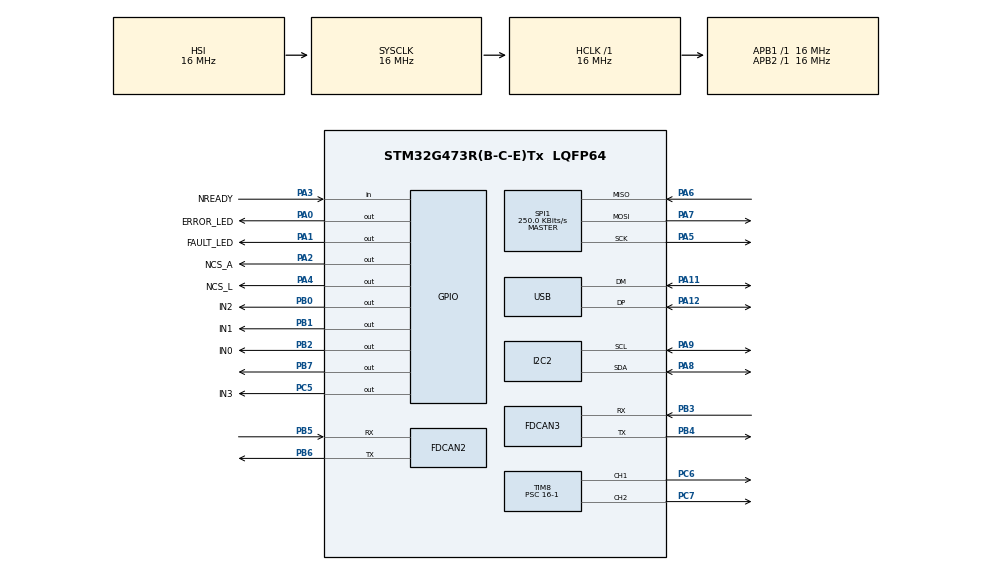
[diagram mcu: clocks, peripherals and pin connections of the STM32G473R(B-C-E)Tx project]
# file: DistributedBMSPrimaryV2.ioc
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FDCAN2.CalculateBaudRateNominal=500000
FDCAN2.CalculateTimeBitNominal=2000
FDCAN2.CalculateTimeQuantumNominal=250.0
FDCAN2.NominalPrescaler=4
FDCAN2.NominalTimeSeg1=3
FDCAN2.NominalTimeSeg2=4
FDCAN3.CalculateBaudRateNominal=500000
FDCAN3.CalculateTimeBitNominal=2000
FDCAN3.CalculateTimeQuantumNominal=250.0
FDCAN3.NominalPrescaler=4
FDCAN3.NominalTimeSeg1=3
FDCAN3.NominalTimeSeg2=4
FREERTOS.Tasks01=defaultTask,24,128,StartDefaultTask,Default,NULL,Dynamic,NULL,NULL
FREERTOS.configUSE_NEWLIB_REENTRANT=1
I2C2.Timing=0x00503D58
Mcu.Family=STM32G4
Mcu.Name=STM32G473R(B-C-E)Tx
Mcu.Package=LQFP64
NVIC.FDCAN2_IT0_IRQn=true\:5\:0\:false\:false\:true\:true\:true\:true\:true
NVIC.FDCAN3_IT0_IRQn=true\:5\:0\:false\:false\:true\:true\:true\:true\:true
NVIC.PriorityGroup=NVIC_PRIORITYGROUP_4
NVIC.TIM3_IRQn=true\:15\:0\:false\:false\:true\:false\:false\:true\:true
NVIC.TimeBase=TIM3_IRQn
NVIC.TimeBaseIP=TIM3
PA0.GPIO_Label=ERROR_LED
PA0.Signal=GPIO_Output
PA1.GPIO_Label=FAULT_LED
PA1.Signal=GPIO_Output
PA11.Mode=Device
PA11.Signal=USB_DM
PA12.Mode=Device
PA12.Signal=USB_DP
PA13.Mode=Serial_Wire
PA13.Signal=SYS_JTMS-SWDIO
PA14.Mode=Serial_Wire
PA14.Signal=SYS_JTCK-SWCLK
PA2.GPIO_Label=NCS_A
PA2.Signal=GPIO_Output
PA3.GPIO_Label=NREADY
PA3.Signal=GPIO_Input
PA4.GPIO_Label=NCS_L
PA4.Signal=GPIO_Output
PA5.Mode=Full_Duplex_Master
PA5.Signal=SPI1_SCK
PA6.Mode=Full_Duplex_Master
PA6.Signal=SPI1_MISO
PA7.Mode=Full_Duplex_Master
PA7.Signal=SPI1_MOSI
PA8.Mode=I2C
PA8.Signal=I2C2_SDA
PA9.Mode=I2C
PA9.Signal=I2C2_SCL
PB0.GPIO_Label=IN2
PB0.Signal=GPIO_Output
PB1.GPIO_Label=IN1
PB1.Signal=GPIO_Output
PB2.GPIO_Label=IN0
PB2.Signal=GPIO_Output
PB3.Mode=FDCAN_Activate
PB3.Signal=FDCAN3_RX
PB4.Mode=FDCAN_Activate
PB4.Signal=FDCAN3_TX
PB5.Mode=FDCAN_Activate
PB5.Signal=FDCAN2_RX
PB6.Mode=FDCAN_Activate
PB6.Signal=FDCAN2_TX
PB7.Signal=GPIO_Output
PC5.GPIO_Label=IN3
PC5.Signal=GPIO_Output
PC6.Signal=S_TIM8_CH1
PC7.Signal=S_TIM8_CH2
ProjectManager.HeapSize=0x200
ProjectManager.StackSize=0x400
ProjectManager.TargetToolchain=STM32CubeIDE
RCC.AHBFreq_Value=16000000
RCC.APB1Freq_Value=16000000
RCC.APB1TimFreq_Value=16000000
RCC.APB2Freq_Value=16000000
RCC.APB2TimFreq_Value=16000000
RCC.CortexFreq_Value=16000000
RCC.EXTERNAL_CLOCK_VALUE=12288000
RCC.HCLKFreq_Value=16000000
RCC.HSE_VALUE=8000000
RCC.HSI48_VALUE=48000000
RCC.HSI_VALUE=16000000
RCC.LSE_VALUE=32768
RCC.PLLN=12
RCC.PLLQ=RCC_PLLQ_DIV4
RCC.SYSCLKFreq_VALUE=16000000
RCC.USBFreq_Value=48000000
RCC.VCOOutputFreq_Value=192000000
SH.S_TIM8_CH1.0=TIM8_CH1,PWM Generation1 CH1
SH.S_TIM8_CH2.0=TIM8_CH2,PWM Generation2 CH2
SPI1.BaudRatePrescaler=SPI_BAUDRATEPRESCALER_64
SPI1.CalculateBaudRate=250.0 KBits/s
SPI1.DataSize=SPI_DATASIZE_8BIT
SPI1.Direction=SPI_DIRECTION_2LINES
SPI1.Mode=SPI_MODE_MASTER
SPI1.VirtualType=VM_MASTER
TIM8.Channel-PWM\ Generation1\ CH1=TIM_CHANNEL_1
TIM8.Channel-PWM\ Generation2\ CH2=TIM_CHANNEL_2
TIM8.OCMode_PWM-PWM\ Generation1\ CH1=TIM_OCMODE_PWM2
TIM8.PeriodNoDither=40-1
TIM8.Prescaler=16-1
VP_FREERTOS_VS_CMSIS_V2.Mode=CMSIS_V2
VP_SYS_VS_DBSignals.Mode=DisableDeadBatterySignals
VP_SYS_VS_tim3.Mode=TIM3
VP_TIM8_VS_ClockSourceINT.Mode=Internal
board=custom

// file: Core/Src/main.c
/* USER CODE BEGIN Header */
/**
  ******************************************************************************
  * @file           : main.c
  * @brief          : Main program body
  ******************************************************************************
  * @attention
  *
  * Copyright (c) 2026 STMicroelectronics.
  * All rights reserved.
  *
  * This software is licensed under terms that can be found in the LICENSE file
  * in the root directory of this software component.
  * If no LICENSE file comes with this software, it is provided AS-IS.
  *
  ******************************************************************************
  */
/* USER CODE END Header */
#include "main.h"
#include "cmsis_os.h"

FDCAN_HandleTypeDef hfdcan2;
FDCAN_HandleTypeDef hfdcan3;

I2C_HandleTypeDef hi2c2;

SPI_HandleTypeDef hspi1;

TIM_HandleTypeDef htim8;

/* Definitions for defaultTask */
osThreadId_t defaultTaskHandle;
const osThreadAttr_t defaultTask_attributes = {
  .name = "defaultTask",
  .priority = (osPriority_t) osPriorityNormal,
  .stack_size = 128 * 4
};

void SystemClock_Config(void);
static void MX_GPIO_Init(void);
static void MX_FDCAN2_Init(void);
static void MX_FDCAN3_Init(void);
static void MX_SPI1_Init(void);
static void MX_I2C2_Init(void);
static void MX_TIM8_Init(void);
void StartDefaultTask(void *argument);

int main(void)
{

  /* MCU Configuration--------------------------------------------------------*/

  /* Reset of all peripherals, Initializes the Flash interface and the Systick. */
  HAL_Init();

  /* Configure the system clock */
  SystemClock_Config();

  /* Initialize all configured peripherals */
  MX_GPIO_Init();
  MX_FDCAN2_Init();
  MX_FDCAN3_Init();
  MX_SPI1_Init();
  MX_I2C2_Init();
  MX_TIM8_Init();

  /* Init scheduler */
  osKernelInitialize();

  /* Create the thread(s) */
  /* creation of defaultTask */
  defaultTaskHandle = osThreadNew(StartDefaultTask, NULL, &defaultTask_attributes);

  /* Start scheduler */
  osKernelStart();

  /* We should never get here as control is now taken by the scheduler */

  /* Infinite loop */
  while (1)
  {

  }
}

void SystemClock_Config(void)
{
  RCC_OscInitTypeDef RCC_OscInitStruct = {0};
  RCC_ClkInitTypeDef RCC_ClkInitStruct = {0};

  /** Configure the main internal regulator output voltage
  */
  HAL_PWREx_ControlVoltageScaling(PWR_REGULATOR_VOLTAGE_SCALE1);

  /** Initializes the RCC Oscillators according to the specified parameters
  * in the RCC_OscInitTypeDef structure.
  */
  RCC_OscInitStruct.OscillatorType = RCC_OSCILLATORTYPE_HSI;
  RCC_OscInitStruct.HSIState = RCC_HSI_ON;
  RCC_OscInitStruct.HSICalibrationValue = RCC_HSICALIBRATION_DEFAULT;
  RCC_OscInitStruct.PLL.PLLState = RCC_PLL_NONE;
  if (HAL_RCC_OscConfig(&RCC_OscInitStruct) != HAL_OK)
  {
    Error_Handler();
  }

  /** Initializes the CPU, AHB and APB buses clocks
  */
  RCC_ClkInitStruct.ClockType = RCC_CLOCKTYPE_HCLK|RCC_CLOCKTYPE_SYSCLK
                              |RCC_CLOCKTYPE_PCLK1|RCC_CLOCKTYPE_PCLK2;
  RCC_ClkInitStruct.SYSCLKSource = RCC_SYSCLKSOURCE_HSI;
  RCC_ClkInitStruct.AHBCLKDivider = RCC_SYSCLK_DIV1;
  RCC_ClkInitStruct.APB1CLKDivider = RCC_HCLK_DIV1;
  RCC_ClkInitStruct.APB2CLKDivider = RCC_HCLK_DIV1;

  if (HAL_RCC_ClockConfig(&RCC_ClkInitStruct, FLASH_LATENCY_0) != HAL_OK)
  {
    Error_Handler();
  }
}

static void MX_FDCAN2_Init(void)
{

  hfdcan2.Instance = FDCAN2;
  hfdcan2.Init.ClockDivider = FDCAN_CLOCK_DIV1;
  hfdcan2.Init.FrameFormat = FDCAN_FRAME_CLASSIC;
  hfdcan2.Init.Mode = FDCAN_MODE_NORMAL;
  hfdcan2.Init.AutoRetransmission = DISABLE;
  hfdcan2.Init.TransmitPause = DISABLE;
  hfdcan2.Init.ProtocolException = DISABLE;
  hfdcan2.Init.NominalPrescaler = 4;
  hfdcan2.Init.NominalSyncJumpWidth = 1;
  hfdcan2.Init.NominalTimeSeg1 = 3;
  hfdcan2.Init.NominalTimeSeg2 = 4;
  hfdcan2.Init.DataPrescaler = 1;
  hfdcan2.Init.DataSyncJumpWidth = 1;
  hfdcan2.Init.DataTimeSeg1 = 1;
  hfdcan2.Init.DataTimeSeg2 = 1;
  hfdcan2.Init.StdFiltersNbr = 0;
  hfdcan2.Init.ExtFiltersNbr = 0;
  hfdcan2.Init.TxFifoQueueMode = FDCAN_TX_FIFO_OPERATION;
  if (HAL_FDCAN_Init(&hfdcan2) != HAL_OK)
  {
    Error_Handler();
  }

}

static void MX_FDCAN3_Init(void)
{

  hfdcan3.Instance = FDCAN3;
  hfdcan3.Init.ClockDivider = FDCAN_CLOCK_DIV1;
  hfdcan3.Init.FrameFormat = FDCAN_FRAME_CLASSIC;
  hfdcan3.Init.Mode = FDCAN_MODE_NORMAL;
  hfdcan3.Init.AutoRetransmission = DISABLE;
  hfdcan3.Init.TransmitPause = DISABLE;
  hfdcan3.Init.ProtocolException = DISABLE;
  hfdcan3.Init.NominalPrescaler = 4;
  hfdcan3.Init.NominalSyncJumpWidth = 1;
  hfdcan3.Init.NominalTimeSeg1 = 3;
  hfdcan3.Init.NominalTimeSeg2 = 4;
  hfdcan3.Init.DataPrescaler = 1;
  hfdcan3.Init.DataSyncJumpWidth = 1;
  hfdcan3.Init.DataTimeSeg1 = 1;
  hfdcan3.Init.DataTimeSeg2 = 1;
  hfdcan3.Init.StdFiltersNbr = 0;
  hfdcan3.Init.ExtFiltersNbr = 0;
  hfdcan3.Init.TxFifoQueueMode = FDCAN_TX_FIFO_OPERATION;
  if (HAL_FDCAN_Init(&hfdcan3) != HAL_OK)
  {
    Error_Handler();
  }

}

static void MX_I2C2_Init(void)
{

  hi2c2.Instance = I2C2;
  hi2c2.Init.Timing = 0x00503D58;
  hi2c2.Init.OwnAddress1 = 0;
  hi2c2.Init.AddressingMode = I2C_ADDRESSINGMODE_7BIT;
  hi2c2.Init.DualAddressMode = I2C_DUALADDRESS_DISABLE;
  hi2c2.Init.OwnAddress2 = 0;
  hi2c2.Init.OwnAddress2Masks = I2C_OA2_NOMASK;
  hi2c2.Init.GeneralCallMode = I2C_GENERALCALL_DISABLE;
  hi2c2.Init.NoStretchMode = I2C_NOSTRETCH_DISABLE;
  if (HAL_I2C_Init(&hi2c2) != HAL_OK)
  {
    Error_Handler();
  }

  /** Configure Analogue filter
  */
  if (HAL_I2CEx_ConfigAnalogFilter(&hi2c2, I2C_ANALOGFILTER_ENABLE) != HAL_OK)
  {
    Error_Handler();
  }

  /** Configure Digital filter
  */
  if (HAL_I2CEx_ConfigDigitalFilter(&hi2c2, 0) != HAL_OK)
  {
    Error_Handler();
  }

}

static void MX_SPI1_Init(void)
{

  /* SPI1 parameter configuration*/
  hspi1.Instance = SPI1;
  hspi1.Init.Mode = SPI_MODE_MASTER;
  hspi1.Init.Direction = SPI_DIRECTION_2LINES;
  hspi1.Init.DataSize = SPI_DATASIZE_8BIT;
  hspi1.Init.CLKPolarity = SPI_POLARITY_LOW;
  hspi1.Init.CLKPhase = SPI_PHASE_1EDGE;
  hspi1.Init.NSS = SPI_NSS_SOFT;
  hspi1.Init.BaudRatePrescaler = SPI_BAUDRATEPRESCALER_64;
  hspi1.Init.FirstBit = SPI_FIRSTBIT_MSB;
  hspi1.Init.TIMode = SPI_TIMODE_DISABLE;
  hspi1.Init.CRCCalculation = SPI_CRCCALCULATION_DISABLE;
  hspi1.Init.CRCPolynomial = 7;
  hspi1.Init.CRCLength = SPI_CRC_LENGTH_DATASIZE;
  hspi1.Init.NSSPMode = SPI_NSS_PULSE_ENABLE;
  if (HAL_SPI_Init(&hspi1) != HAL_OK)
  {
    Error_Handler();
  }

}

static void MX_TIM8_Init(void)
{

  TIM_ClockConfigTypeDef sClockSourceConfig = {0};
  TIM_MasterConfigTypeDef sMasterConfig = {0};
  TIM_OC_InitTypeDef sConfigOC = {0};
  TIM_BreakDeadTimeConfigTypeDef sBreakDeadTimeConfig = {0};

  htim8.Instance = TIM8;
  htim8.Init.Prescaler = 16-1;
  htim8.Init.CounterMode = TIM_COUNTERMODE_UP;
  htim8.Init.Period = 39;
  htim8.Init.ClockDivision = TIM_CLOCKDIVISION_DIV1;
  htim8.Init.RepetitionCounter = 0;
  htim8.Init.AutoReloadPreload = TIM_AUTORELOAD_PRELOAD_DISABLE;
  if (HAL_TIM_Base_Init(&htim8) != HAL_OK)
  {
    Error_Handler();
  }
  sClockSourceConfig.ClockSource = TIM_CLOCKSOURCE_INTERNAL;
  if (HAL_TIM_ConfigClockSource(&htim8, &sClockSourceConfig) != HAL_OK)
  {
    Error_Handler();
  }
  if (HAL_TIM_PWM_Init(&htim8) != HAL_OK)
  {
    Error_Handler();
  }
  sMasterConfig.MasterOutputTrigger = TIM_TRGO_RESET;
  sMasterConfig.MasterOutputTrigger2 = TIM_TRGO2_RESET;
  sMasterConfig.MasterSlaveMode = TIM_MASTERSLAVEMODE_DISABLE;
  if (HAL_TIMEx_MasterConfigSynchronization(&htim8, &sMasterConfig) != HAL_OK)
  {
    Error_Handler();
  }
  sConfigOC.OCMode = TIM_OCMODE_PWM2;
  sConfigOC.Pulse = 0;
  sConfigOC.OCPolarity = TIM_OCPOLARITY_HIGH;
  sConfigOC.OCNPolarity = TIM_OCNPOLARITY_HIGH;
  sConfigOC.OCFastMode = TIM_OCFAST_DISABLE;
  sConfigOC.OCIdleState = TIM_OCIDLESTATE_RESET;
  sConfigOC.OCNIdleState = TIM_OCNIDLESTATE_RESET;
  if (HAL_TIM_PWM_ConfigChannel(&htim8, &sConfigOC, TIM_CHANNEL_1) != HAL_OK)
  {
    Error_Handler();
  }
  sConfigOC.OCMode = TIM_OCMODE_PWM1;
  if (HAL_TIM_PWM_ConfigChannel(&htim8, &sConfigOC, TIM_CHANNEL_2) != HAL_OK)
  {
    Error_Handler();
  }
  sBreakDeadTimeConfig.OffStateRunMode = TIM_OSSR_DISABLE;
  sBreakDeadTimeConfig.OffStateIDLEMode = TIM_OSSI_DISABLE;
  sBreakDeadTimeConfig.LockLevel = TIM_LOCKLEVEL_OFF;
  sBreakDeadTimeConfig.DeadTime = 0;
  sBreakDeadTimeConfig.BreakState = TIM_BREAK_DISABLE;
  sBreakDeadTimeConfig.BreakPolarity = TIM_BREAKPOLARITY_HIGH;
  sBreakDeadTimeConfig.BreakFilter = 0;
  sBreakDeadTimeConfig.BreakAFMode = TIM_BREAK_AFMODE_INPUT;
  sBreakDeadTimeConfig.Break2State = TIM_BREAK2_DISABLE;
  sBreakDeadTimeConfig.Break2Polarity = TIM_BREAK2POLARITY_HIGH;
  sBreakDeadTimeConfig.Break2Filter = 0;
  sBreakDeadTimeConfig.Break2AFMode = TIM_BREAK_AFMODE_INPUT;
  sBreakDeadTimeConfig.AutomaticOutput = TIM_AUTOMATICOUTPUT_DISABLE;
  if (HAL_TIMEx_ConfigBreakDeadTime(&htim8, &sBreakDeadTimeConfig) != HAL_OK)
  {
    Error_Handler();
  }
  HAL_TIM_MspPostInit(&htim8);

}

static void MX_GPIO_Init(void)
{
  GPIO_InitTypeDef GPIO_InitStruct = {0};

  /* GPIO Ports Clock Enable */
  __HAL_RCC_GPIOA_CLK_ENABLE();
  __HAL_RCC_GPIOC_CLK_ENABLE();
  __HAL_RCC_GPIOB_CLK_ENABLE();

  /*Configure GPIO pin Output Level */
  HAL_GPIO_WritePin(GPIOA, ERROR_LED_Pin|FAULT_LED_Pin|NCS_A_Pin|NCS_L_Pin, GPIO_PIN_RESET);

  /*Configure GPIO pin Output Level */
  HAL_GPIO_WritePin(IN0_GPIO_Port, IN0_Pin, GPIO_PIN_RESET);

  /*Configure GPIO pin Output Level */
  HAL_GPIO_WritePin(GPIOB, IN1_Pin|IN2_Pin|IN3_Pin, GPIO_PIN_RESET);

  /*Configure GPIO pins : ERROR_LED_Pin FAULT_LED_Pin NCS_A_Pin NCS_L_Pin */
  GPIO_InitStruct.Pin = ERROR_LED_Pin|FAULT_LED_Pin|NCS_A_Pin|NCS_L_Pin;
  GPIO_InitStruct.Mode = GPIO_MODE_OUTPUT_PP;
  GPIO_InitStruct.Pull = GPIO_NOPULL;
  GPIO_InitStruct.Speed = GPIO_SPEED_FREQ_LOW;
  HAL_GPIO_Init(GPIOA, &GPIO_InitStruct);

  /*Configure GPIO pin : NREADY_Pin */
  GPIO_InitStruct.Pin = NREADY_Pin;
  GPIO_InitStruct.Mode = GPIO_MODE_INPUT;
  GPIO_InitStruct.Pull = GPIO_NOPULL;
  HAL_GPIO_Init(NREADY_GPIO_Port, &GPIO_InitStruct);

  /*Configure GPIO pin : IN0_Pin */
  GPIO_InitStruct.Pin = IN0_Pin;
  GPIO_InitStruct.Mode = GPIO_MODE_OUTPUT_PP;
  GPIO_InitStruct.Pull = GPIO_NOPULL;
  GPIO_InitStruct.Speed = GPIO_SPEED_FREQ_LOW;
  HAL_GPIO_Init(IN0_GPIO_Port, &GPIO_InitStruct);

  /*Configure GPIO pins : IN1_Pin IN2_Pin IN3_Pin */
  GPIO_InitStruct.Pin = IN1_Pin|IN2_Pin|IN3_Pin;
  GPIO_InitStruct.Mode = GPIO_MODE_OUTPUT_PP;
  GPIO_InitStruct.Pull = GPIO_NOPULL;
  GPIO_InitStruct.Speed = GPIO_SPEED_FREQ_LOW;
  HAL_GPIO_Init(GPIOB, &GPIO_InitStruct);

}

void StartDefaultTask(void *argument)
{
  for(;;)
  {
    osDelay(1);
  }
}

void HAL_TIM_PeriodElapsedCallback(TIM_HandleTypeDef *htim)
{
  if (htim->Instance == TIM3) {
    HAL_IncTick();
  }
}

void Error_Handler(void)
{
  __disable_irq();
  while (1)
  {
  }
}

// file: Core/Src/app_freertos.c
/* USER CODE BEGIN Header */
/**
  ******************************************************************************
  * File Name          : app_freertos.c
  * Description        : Code for freertos applications
  ******************************************************************************
  * @attention
  *
  * Copyright (c) 2026 STMicroelectronics.
  * All rights reserved.
  *
  * This software is licensed under terms that can be found in the LICENSE file
  * in the root directory of this software component.
  * If no LICENSE file comes with this software, it is provided AS-IS.
  *
  ******************************************************************************
  */
/* USER CODE END Header */

#include "FreeRTOS.h"
#include "task.h"
#include "main.h"

/* USER CODE BEGIN Application */

#if (configCHECK_FOR_STACK_OVERFLOW > 0)
void vApplicationStackOverflowHook(TaskHandle_t xTask, char *pcTaskName) {
    (void)xTask;
    (void)pcTaskName;
    taskDISABLE_INTERRUPTS();
    for (;;) {
    }
}
#endif

/* USER CODE END Application */
